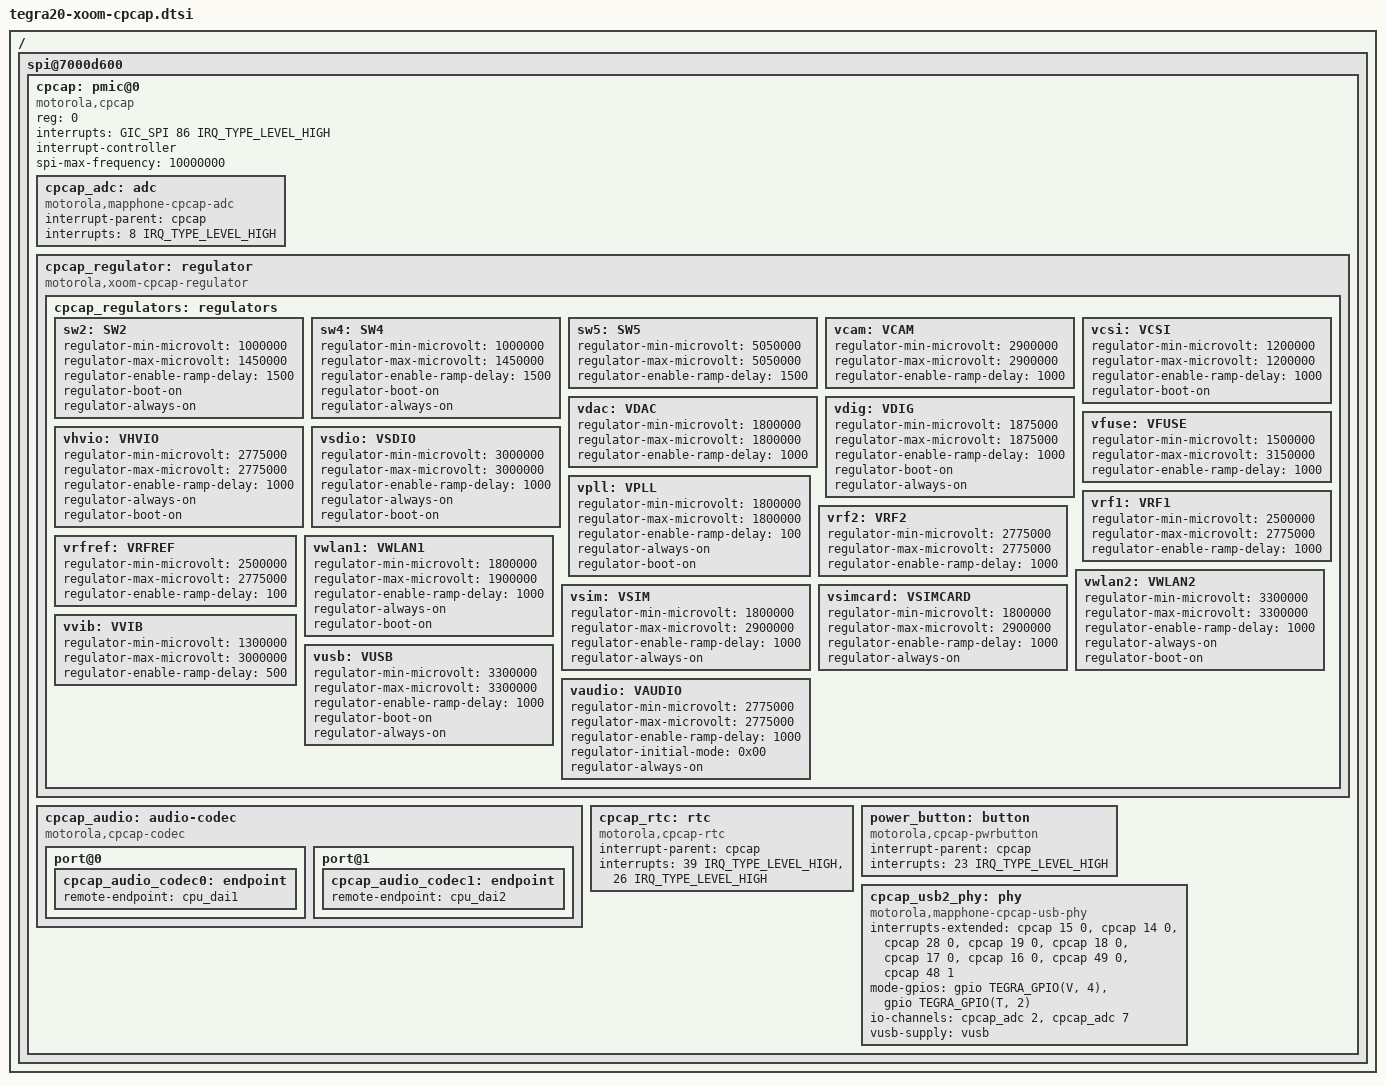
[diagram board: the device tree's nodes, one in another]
/*
 * CPCAP configuration used on the Motorola Xoom
 *
 * This program is free software; you can redistribute it and/or modify
 * it under the terms of the GNU General Public License version 2 as
 * published by the Free Software Foundation.
 */

/{
	spi@7000d600 {
		cpcap: pmic@0 {
			compatible = "motorola,cpcap", "st,6556002";
			reg = <0>;	/* cs0 */
/*			interrupt-parent = <&intc>; */
			interrupts = <GIC_SPI 86 IRQ_TYPE_LEVEL_HIGH>;
			interrupt-controller;
			#interrupt-cells = <2>;
			#address-cells = <1>;
			#size-cells = <0>;
			spi-max-frequency = <10000000>;

			cpcap_adc: adc {
				compatible = "motorola,mapphone-cpcap-adc";
				interrupt-parent = <&cpcap>; 
				interrupts = <8 IRQ_TYPE_LEVEL_HIGH>;
				interrupt-names = "adcdone";
				#io-channel-cells = <1>;
			};

			cpcap_regulator: regulator {
				compatible = "motorola,xoom-cpcap-regulator";

				cpcap_regulators: regulators {
					sw2: SW2 {
						regulator-min-microvolt = <1000000>;
						regulator-max-microvolt = <1450000>;
						regulator-enable-ramp-delay = <1500>;
						regulator-boot-on;
						regulator-always-on;
					};

					sw4: SW4 {
						regulator-min-microvolt = <1000000>;
						regulator-max-microvolt = <1450000>;
						regulator-enable-ramp-delay = <1500>;
						regulator-boot-on;
						regulator-always-on;
					};

					sw5: SW5 {
						regulator-min-microvolt = <5050000>;
						regulator-max-microvolt = <5050000>;
						regulator-enable-ramp-delay = <1500>;
					};

					vcam: VCAM {
						regulator-min-microvolt = <2900000>;
						regulator-max-microvolt = <2900000>;
						regulator-enable-ramp-delay = <1000>;
					};

					vcsi: VCSI {
						regulator-min-microvolt = <1200000>;
						regulator-max-microvolt = <1200000>;
						regulator-enable-ramp-delay = <1000>;
						regulator-boot-on;
					};

					vdac: VDAC {
						regulator-min-microvolt = <1800000>;
						regulator-max-microvolt = <1800000>;
						regulator-enable-ramp-delay = <1000>;
					};

					vdig: VDIG {
						regulator-min-microvolt = <1875000>;
						regulator-max-microvolt = <1875000>;
						regulator-enable-ramp-delay = <1000>;
						regulator-boot-on;
						regulator-always-on;
					};

					vfuse: VFUSE {
						regulator-min-microvolt = <1500000>;
						regulator-max-microvolt = <3150000>;
						regulator-enable-ramp-delay = <1000>;
					};

					vhvio: VHVIO {
						regulator-min-microvolt = <2775000>;
						regulator-max-microvolt = <2775000>;
						regulator-enable-ramp-delay = <1000>;
						regulator-always-on;
						regulator-boot-on;
					};

					/* Used by eMMC at mmc2 */
					vsdio: VSDIO {
						regulator-min-microvolt = <3000000>;
						regulator-max-microvolt = <3000000>;
						regulator-enable-ramp-delay = <1000>;
						regulator-always-on;
						regulator-boot-on;
					};

					vpll: VPLL {
						regulator-min-microvolt = <1800000>;
						regulator-max-microvolt = <1800000>;
						regulator-enable-ramp-delay = <100>;
						regulator-always-on;
						regulator-boot-on;
					};

					vrf1: VRF1 {
						regulator-min-microvolt = <2500000>;
						regulator-max-microvolt = <2775000>;
						regulator-enable-ramp-delay = <1000>;
					};

					vrf2: VRF2 {
						regulator-min-microvolt = <2775000>;
						regulator-max-microvolt = <2775000>;
						regulator-enable-ramp-delay = <1000>;
					};

					vrfref: VRFREF {
						regulator-min-microvolt = <2500000>;
						regulator-max-microvolt = <2775000>;
						regulator-enable-ramp-delay = <100>;
					};

					vwlan1: VWLAN1 {
						regulator-min-microvolt = <1800000>;
						regulator-max-microvolt = <1900000>;
						regulator-enable-ramp-delay = <1000>;
						regulator-always-on;
						regulator-boot-on;
					};

					vwlan2: VWLAN2 {
						regulator-min-microvolt = <3300000>;
						regulator-max-microvolt = <3300000>;
						regulator-enable-ramp-delay = <1000>;
						regulator-always-on;
						regulator-boot-on;
					};

					vsim: VSIM {
						regulator-min-microvolt = <1800000>;
						regulator-max-microvolt = <2900000>;
						regulator-enable-ramp-delay = <1000>;
						regulator-always-on;
					};

					vsimcard: VSIMCARD {
						regulator-min-microvolt = <1800000>;
						regulator-max-microvolt = <2900000>;
						regulator-enable-ramp-delay = <1000>;
						regulator-always-on;
					};

					vvib: VVIB {
						regulator-min-microvolt = <1300000>;
						regulator-max-microvolt = <3000000>;
						regulator-enable-ramp-delay = <500>;
					};

					vusb: VUSB {
						regulator-min-microvolt = <3300000>;
						regulator-max-microvolt = <3300000>;
						regulator-enable-ramp-delay = <1000>;
						regulator-boot-on;
						regulator-always-on;
					};

					vaudio: VAUDIO {
						regulator-min-microvolt = <2775000>;
						regulator-max-microvolt = <2775000>;
						regulator-enable-ramp-delay = <1000>;
						regulator-initial-mode = <0x00>; /* NORMAL */
						regulator-always-on;
					};
				};
			};

			cpcap_audio: audio-codec {
				compatible = "motorola,cpcap-codec";
				#sound-dai-cells = <1>;

				port@0 {
					cpcap_audio_codec0: endpoint {
						remote-endpoint = <&cpu_dai1>;
					};
				};
				port@1 {
					cpcap_audio_codec1: endpoint {
						remote-endpoint = <&cpu_dai2>;
					};
				};
			};

			cpcap_rtc: rtc {
				compatible = "motorola,cpcap-rtc";

				interrupt-parent = <&cpcap>;
				interrupts = <39 IRQ_TYPE_LEVEL_HIGH>,
					     <26 IRQ_TYPE_LEVEL_HIGH>;
				interrupt-names = "rtc_alarm",
						  "rtc_1hz";
			};

			power_button: button {
				compatible = "motorola,cpcap-pwrbutton";

				interrupt-parent = <&cpcap>;
				interrupts = <23 IRQ_TYPE_LEVEL_HIGH>;
			};

			cpcap_usb2_phy: phy {
				compatible = "motorola,mapphone-cpcap-usb-phy";
/*				pinctrl-0 = <&usb_gpio_mux_sel1 &usb_gpio_mux_sel2>;
				pinctrl-1 = <&usb_ulpi_pins>;
				pinctrl-2 = <&usb_utmi_pins>;
				pinctrl-3 = <&uart3_pins>;
				pinctrl-names = "default", "ulpi", "utmi", "uart";
*/				#phy-cells = <0>;
				interrupts-extended = <
					&cpcap 15 0 &cpcap 14 0 &cpcap 28 0 &cpcap 19 0
					&cpcap 18 0 &cpcap 17 0 &cpcap 16 0 &cpcap 49 0
					&cpcap 48 1
				>;
				interrupt-names =
					"id_ground", "id_float", "se0conn", "vbusvld",
					"sessvld", "sessend", "se1", "dm", "dp";
				mode-gpios = <&gpio TEGRA_GPIO(V, 4) GPIO_ACTIVE_HIGH
					      &gpio TEGRA_GPIO(T, 2) GPIO_ACTIVE_HIGH>;
				io-channels = <&cpcap_adc 2>, <&cpcap_adc 7>;
				io-channel-names = "vbus", "id";
				vusb-supply = <&vusb>;
			};

/*			led_red: led-red {
				compatible = "motorola,cpcap-led-red";
				vdd-supply = <&sw5>;
				label = "status-led:red";
			};

			led_green: led-green {
				compatible = "motorola,cpcap-led-green";
				vdd-supply = <&sw5>;
				label = "status-led:green";
			};

			led_blue: led-blue {
				compatible = "motorola,cpcap-led-blue";
				vdd-supply = <&sw5>;
				label = "status-led:blue";
			};

			led_adl: led-adl {
				compatible = "motorola,cpcap-led-adl";
				vdd-supply = <&sw5>;
				label = "button-backlight";
			};

			led_cp: led-cp {
				compatible = "motorola,cpcap-led-cp";
				vdd-supply = <&sw5>;
				label = "shift-key-light";
			};
*/		};
	};
};


